AUTOSAR XML (schema 00049)
package /Application/DltConfig
  dlt log channel to process mapping DltLogChannelToProcessMapping_SOA_DMS_TO_SOA_DMS: dlt-log-channel=SOA_DMS, process=SOA_DMS
package /Application/Executable
  executable SOA_DMS: category=APPLICATION_LEVEL, logging-behavior=USES-LOGGING, reporting-behavior=REPORTS-EXECUTION-STATE, version=1.0.0
    root sw component prototype AA: application-type=SOA_DMS
package /Application/Manifest
  service instance to port prototype mapping SOA_DMS_AA_PPort_SOA_DMS: port-prototype=AA.PPort_SOA_DMS, process=SOA_DMS, service-instance=Provider_SoaDms
  service instance to port prototype mapping SOA_DMS_AA_RPort_Zone1VehicleInfo: port-prototype=AA.RPort_Zone1VehicleInfo, process=SOA_DMS, service-instance=Consumer_SoaDms_VehicleInfo
  service instance to port prototype mapping SOA_DMS_AA_RPort_Zone5Dms: port-prototype=AA.RPort_Zone5Dms, process=SOA_DMS, service-instance=Consumer_Zone5Dms
package /Application/Package/SOA_DMS/SoftwareCluster_1_0_0
  software cluster SOA_DMS_SoftwareCluster: category=APPLICATION_LAYER, contained-ar-element=SOA_DMS, contained-package-element=[SOA_DMS_AA_PPort_SOA_DMS, SOA_DMS_AA_RPort_Zone1VehicleInfo, SOA_DMS_AA_RPort_Zone5Dms], contained-process=SOA_DMS, vendor-id=79, vendor-signature=ParaCertificate, version=1.0.0
package /Application/Package/SOA_DMS/SoftwareCluster_1_0_1
  software cluster SOA_DMS_SoftwareCluster: category=APPLICATION_LAYER, contained-ar-element=SOA_DMS, contained-package-element=[SOA_DMS_AA_PPort_SOA_DMS, SOA_DMS_AA_RPort_Zone1VehicleInfo, SOA_DMS_AA_RPort_Zone5Dms], contained-process=SOA_DMS, vendor-id=79, vendor-signature=ParaCertificate, version=1.0.1
package /Application/Package/SOA_DMS/SoftwareCluster_1_0_2
  software cluster SOA_DMS_SoftwareCluster: category=APPLICATION_LAYER, contained-ar-element=SOA_DMS, contained-package-element=[SOA_DMS_AA_PPort_SOA_DMS, SOA_DMS_AA_RPort_Zone1VehicleInfo, SOA_DMS_AA_RPort_Zone5Dms], contained-process=SOA_DMS, vendor-id=79, vendor-signature=ParaCertificate, version=1.0.2
package /Application/Package/SOA_DMS/SoftwarePackage
  software package SOA_DMS_InstallSoftwarePackage_1_0_0: action-type=INSTALL, compressed-software-package-size=0, maximum-supported-ucm-version=1.0.0, minimum-supported-ucm-version=1.0.0, packager-id=79, packager-signature=ParaCertificate, post-verification-reboot=false, pre-activate=SC.Off, pre-activation-reboot=false, software-cluster=SoftwareCluster_1_0_0/SOA_DMS_SoftwareCluster, uncompressed-software-cluster-size=0, verify=SC.Verify
  software package SOA_DMS_RemoveSoftwarePackage_1_0_2: action-type=REMOVE, compressed-software-package-size=0, maximum-supported-ucm-version=1.0.0, minimum-supported-ucm-version=1.0.0, packager-id=79, packager-signature=ParaCertificate, post-verification-reboot=false, pre-activate=SC.Off, pre-activation-reboot=false, software-cluster=SoftwareCluster_1_0_2/SOA_DMS_SoftwareCluster, uncompressed-software-cluster-size=0, verify=SC.Verify
  software package SOA_DMS_UpdateSoftwarePackage_1_0_1: action-type=UPDATE, compressed-software-package-size=0, maximum-supported-ucm-version=1.0.0, minimum-supported-ucm-version=1.0.0, packager-id=79, packager-signature=ParaCertificate, post-verification-reboot=false, pre-activate=SC.Off, pre-activation-reboot=false, software-cluster=SoftwareCluster_1_0_1/SOA_DMS_SoftwareCluster, uncompressed-software-cluster-size=0, verify=SC.Verify
package /Application/Package/SOA_DMS/VehiclePackage
  vehicle package SOA_DMS_InstallVehiclePackage_1_0_0: vehicle-driver-notification{approval-required=true, notification-state=PROCESS}, packager-signature=ParaCertificate
    rollout-qualifications:
      vehicle rollout step RolloutQualification0
        ucm-processings:
          ucm step UcmProcessing0: ucm=SOA_DMS_InstallVehiclePackage_1_0_0/EEVP_UCM
            software package step SoftwarePackageStep0: process=SOA_DMS_InstallSoftwarePackage_1_0_0, transfers=software-package-storing={storing=UCM, transfer=SOA_DMS_InstallSoftwarePackage_1_0_0}
    ucm description EEVP_UCM: identifier=EEVP_UCM
  vehicle package SOA_DMS_RemoveVehiclePackage_1_0_2: vehicle-driver-notification{approval-required=true, notification-state=PROCESS}, packager-signature=ParaCertificate
    rollout-qualifications:
      vehicle rollout step RolloutQualification0
        ucm-processings:
          ucm step UcmProcessing0: ucm=SOA_DMS_RemoveVehiclePackage_1_0_2/EEVP_UCM
            software package step SoftwarePackageStep0: process=SOA_DMS_RemoveSoftwarePackage_1_0_2, transfers=software-package-storing={storing=UCM, transfer=SOA_DMS_RemoveSoftwarePackage_1_0_2}
    ucm description EEVP_UCM: identifier=EEVP_UCM
  vehicle package SOA_DMS_UpdateVehiclePackage_1_0_1: vehicle-driver-notification{approval-required=true, notification-state=PROCESS}, packager-signature=ParaCertificate
    rollout-qualifications:
      vehicle rollout step RolloutQualification0
        ucm-processings:
          ucm step UcmProcessing0: ucm=SOA_DMS_UpdateVehiclePackage_1_0_1/EEVP_UCM
            software package step SoftwarePackageStep0: process=SOA_DMS_UpdateSoftwarePackage_1_0_1, transfers=software-package-storing={storing=UCM, transfer=SOA_DMS_UpdateSoftwarePackage_1_0_1}
    ucm description EEVP_UCM: identifier=EEVP_UCM
package /Application/Process
  process SOA_DMS: executable=SOA_DMS, state-dependent-startup-config{function-group-state=[SC.On, SC.Verify], resource-group=DefaultResourceGroup, startup-config=SOA}
    process state machine SOA_DMS: type=ProcessState
package /Application/SwComponent
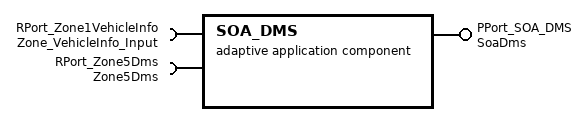
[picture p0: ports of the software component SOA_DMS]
  adaptive application sw component type SOA_DMS
    provide port PPort_SOA_DMS: provided-interface=SoaDms
    require port RPort_Zone1VehicleInfo: required-interface=Zone_VehicleInfo_Input
    require port RPort_Zone5Dms: required-interface=Zone5Dms
